# dsPIC33FJ64GS606 register map
Vendor: Microchip; Series: dsPIC33FJ64GS; File version: 1.4.228
Registers are 16-bit, read-write, no defined reset value unless marked. A register's access mark holds for its fields unless they carry their own. Offsets are from the block's base; [hi:lo] are bit positions; {n}, {i} and the like mark numbered series.

## CAN1 — CAN1 peripheral registers
Base 0x00000600
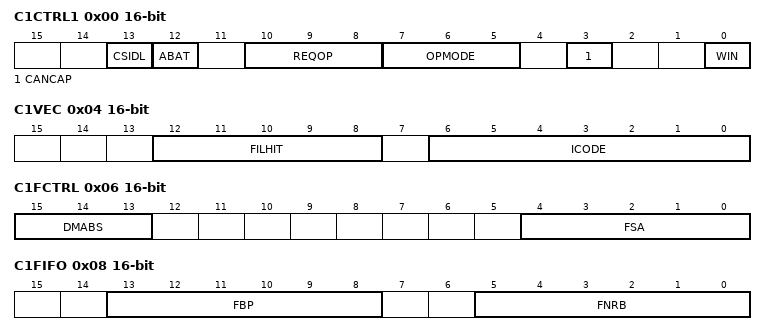
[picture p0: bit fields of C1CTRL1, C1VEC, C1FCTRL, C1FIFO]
0x00 C1CTRL1
  [13] CSIDL — C1CTRL1 field CSIDL
  [12] ABAT — C1CTRL1 field ABAT
  [10:8] REQOP — C1CTRL1 field REQOP
  [7:5] OPMODE — C1CTRL1 field OPMODE
  [3] CANCAP — C1CTRL1 field CANCAP
  [0] WIN — C1CTRL1 field WIN
0x02 C1CTRL2
  [4:0] DNCNT — C1CTRL2 field DNCNT
0x04 C1VEC
  [12:8] FILHIT — C1VEC field FILHIT
  [6:0] ICODE — C1VEC field ICODE
0x06 C1FCTRL
  [15:13] DMABS — C1FCTRL field DMABS
  [4:0] FSA — C1FCTRL field FSA
0x08 C1FIFO
  [13:8] FBP — C1FIFO field FBP
  [5:0] FNRB — C1FIFO field FNRB
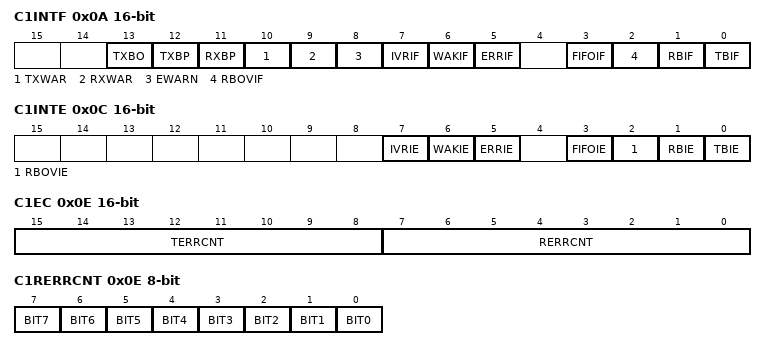
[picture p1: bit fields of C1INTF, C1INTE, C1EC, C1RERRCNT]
0x0A C1INTF
  [13] TXBO — C1INTF field TXBO
  [12] TXBP — C1INTF field TXBP
  [11] RXBP — C1INTF field RXBP
  [10] TXWAR — C1INTF field TXWAR
  [9] RXWAR — C1INTF field RXWAR
  [8] EWARN — C1INTF field EWARN
  [7] IVRIF — C1INTF field IVRIF
  [6] WAKIF — C1INTF field WAKIF
  [5] ERRIF — C1INTF field ERRIF
  [3] FIFOIF — C1INTF field FIFOIF
  [2] RBOVIF — C1INTF field RBOVIF
  [1] RBIF — C1INTF field RBIF
  [0] TBIF — C1INTF field TBIF
0x0C C1INTE
  [7] IVRIE — C1INTE field IVRIE
  [6] WAKIE — C1INTE field WAKIE
  [5] ERRIE — C1INTE field ERRIE
  [3] FIFOIE — C1INTE field FIFOIE
  [2] RBOVIE — C1INTE field RBOVIE
  [1] RBIE — C1INTE field RBIE
  [0] TBIE — C1INTE field TBIE
0x0E C1EC
  [15:8] TERRCNT — C1EC field TERRCNT
  [7:0] RERRCNT — C1EC field RERRCNT
0x0E C1RERRCNT 8-bit
  [n] BIT{n} (n=0..7) — C1RERRCNT bit {n}
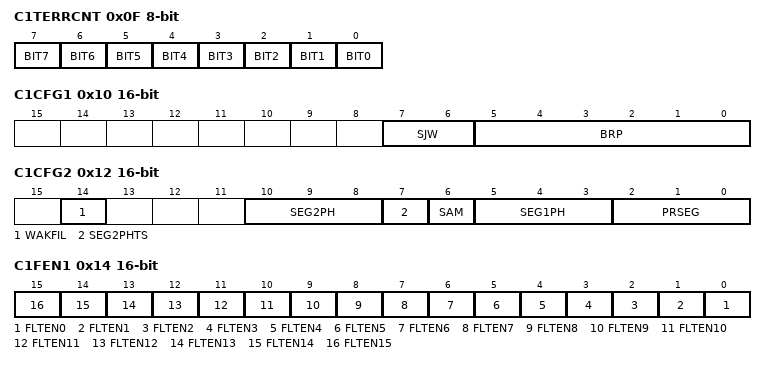
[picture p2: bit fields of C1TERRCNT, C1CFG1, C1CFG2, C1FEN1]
0x0F C1TERRCNT 8-bit
  [n] BIT{n} (n=0..7) — C1TERRCNT bit {n}
0x10 C1CFG1
  [7:6] SJW — C1CFG1 field SJW
  [5:0] BRP — C1CFG1 field BRP
0x12 C1CFG2
  [14] WAKFIL — C1CFG2 field WAKFIL
  [10:8] SEG2PH — C1CFG2 field SEG2PH
  [7] SEG2PHTS — C1CFG2 field SEG2PHTS
  [6] SAM — C1CFG2 field SAM
  [5:3] SEG1PH — C1CFG2 field SEG1PH
  [2:0] PRSEG — C1CFG2 field PRSEG
0x14 C1FEN1
  [n] FLTEN{n} (n=0..15) — C1FEN1 field FLTEN{n}
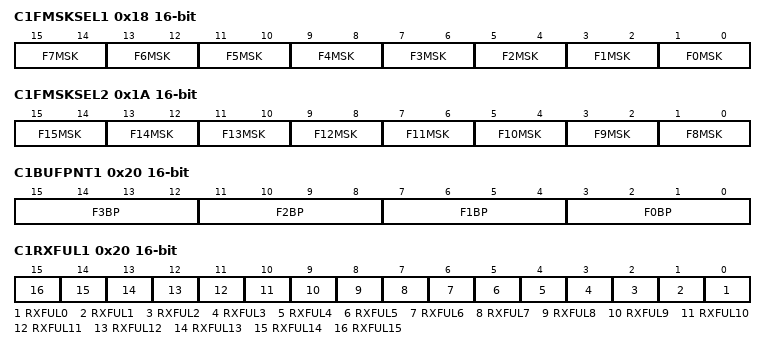
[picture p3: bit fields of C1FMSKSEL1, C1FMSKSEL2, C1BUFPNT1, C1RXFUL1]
0x18 C1FMSKSEL1
  [2n+1:2n] F{n}MSK (n=0..7) — C1FMSKSEL1 field F{n}MSK
0x1A C1FMSKSEL2
  [2n-15:2n-16] F{n}MSK (n=8..15) — C1FMSKSEL2 field F{n}MSK
0x20 C1BUFPNT1
  [4n+3:4n] F{n}BP (n=0..3) — C1BUFPNT1 field F{n}BP
0x20 C1RXFUL1
  [n] RXFUL{n} (n=0..15) — C1RXFUL1 field RXFUL{n}
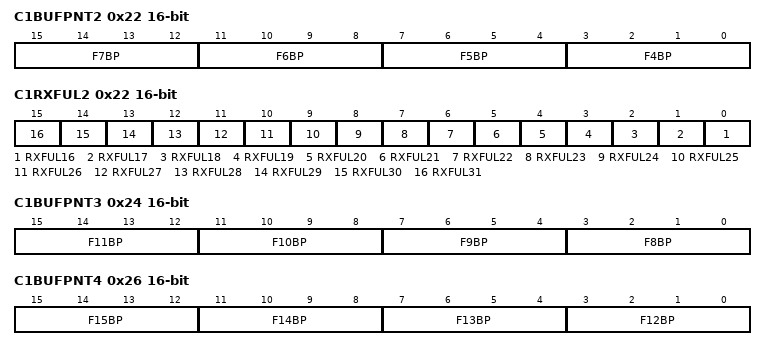
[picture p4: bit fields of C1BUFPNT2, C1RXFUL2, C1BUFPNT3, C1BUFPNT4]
0x22 C1BUFPNT2
  [4n-13:4n-16] F{n}BP (n=4..7) — C1BUFPNT2 field F{n}BP
0x22 C1RXFUL2
  [n-16] RXFUL{n} (n=16..31) — C1RXFUL2 field RXFUL{n}
0x24 C1BUFPNT3
  [4n-29:4n-32] F{n}BP (n=8..11) — C1BUFPNT3 field F{n}BP
0x26 C1BUFPNT4
  [4n-45:4n-48] F{n}BP (n=12..15) — C1BUFPNT4 field F{n}BP
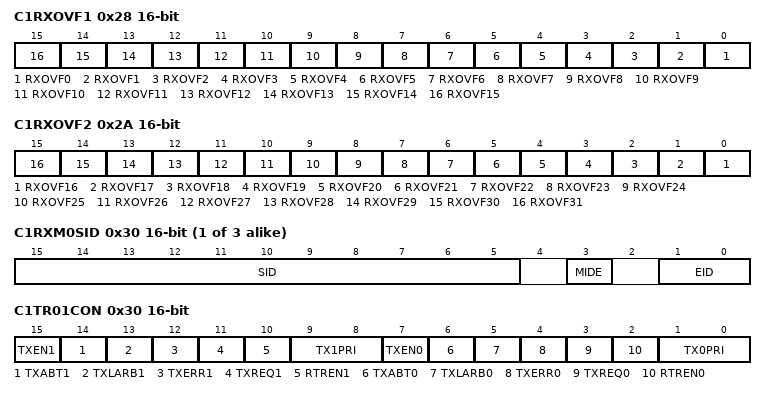
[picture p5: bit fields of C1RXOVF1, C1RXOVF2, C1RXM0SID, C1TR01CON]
0x28 C1RXOVF1
  [n] RXOVF{n} (n=0..15) — C1RXOVF1 field RXOVF{n}
0x2A C1RXOVF2
  [n-16] RXOVF{n} (n=16..31) — C1RXOVF2 field RXOVF{n}
{0x30+4i} C1RXM{i}SID (i=0..2)
  [15:5] SID — C1RXM{i}SID field SID
  [3] MIDE — C1RXM{i}SID field MIDE
  [1:0] EID — C1RXM{i}SID field EID
0x30 C1TR01CON
  [15] TXEN1 — C1TR01CON field TXEN1
  [14] TXABT1 — C1TR01CON field TXABT1
  [13] TXLARB1 — C1TR01CON field TXLARB1
  [12] TXERR1 — C1TR01CON field TXERR1
  [11] TXREQ1 — C1TR01CON field TXREQ1
  [10] RTREN1 — C1TR01CON field RTREN1
  [9:8] TX1PRI — C1TR01CON field TX1PRI
  [7] TXEN0 — C1TR01CON field TXEN0
  [6] TXABT0 — C1TR01CON field TXABT0
  [5] TXLARB0 — C1TR01CON field TXLARB0
  [4] TXERR0 — C1TR01CON field TXERR0
  [3] TXREQ0 — C1TR01CON field TXREQ0
  [2] RTREN0 — C1TR01CON field RTREN0
  [1:0] TX0PRI — C1TR01CON field TX0PRI
{0x32+4i} C1RXM{i}EID (i=0..2)
  [15:0] EID — C1RXM{i}EID field EID
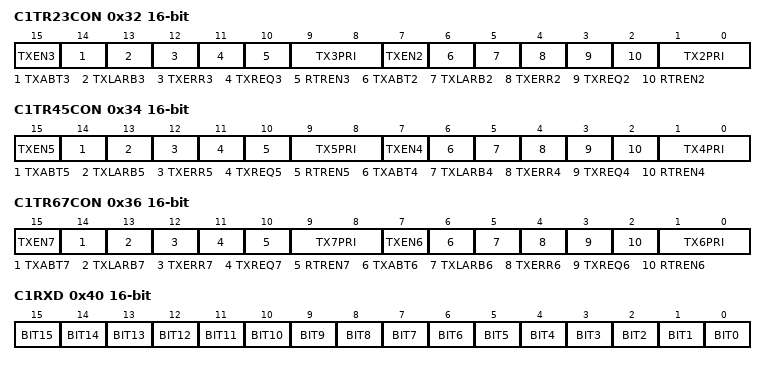
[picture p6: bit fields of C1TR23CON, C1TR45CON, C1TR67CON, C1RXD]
0x32 C1TR23CON
  [15] TXEN3 — C1TR23CON field TXEN3
  [14] TXABT3 — C1TR23CON field TXABT3
  [13] TXLARB3 — C1TR23CON field TXLARB3
  [12] TXERR3 — C1TR23CON field TXERR3
  [11] TXREQ3 — C1TR23CON field TXREQ3
  [10] RTREN3 — C1TR23CON field RTREN3
  [9:8] TX3PRI — C1TR23CON field TX3PRI
  [7] TXEN2 — C1TR23CON field TXEN2
  [6] TXABT2 — C1TR23CON field TXABT2
  [5] TXLARB2 — C1TR23CON field TXLARB2
  [4] TXERR2 — C1TR23CON field TXERR2
  [3] TXREQ2 — C1TR23CON field TXREQ2
  [2] RTREN2 — C1TR23CON field RTREN2
  [1:0] TX2PRI — C1TR23CON field TX2PRI
0x34 C1TR45CON
  [15] TXEN5 — C1TR45CON field TXEN5
  [14] TXABT5 — C1TR45CON field TXABT5
  [13] TXLARB5 — C1TR45CON field TXLARB5
  [12] TXERR5 — C1TR45CON field TXERR5
  [11] TXREQ5 — C1TR45CON field TXREQ5
  [10] RTREN5 — C1TR45CON field RTREN5
  [9:8] TX5PRI — C1TR45CON field TX5PRI
  [7] TXEN4 — C1TR45CON field TXEN4
  [6] TXABT4 — C1TR45CON field TXABT4
  [5] TXLARB4 — C1TR45CON field TXLARB4
  [4] TXERR4 — C1TR45CON field TXERR4
  [3] TXREQ4 — C1TR45CON field TXREQ4
  [2] RTREN4 — C1TR45CON field RTREN4
  [1:0] TX4PRI — C1TR45CON field TX4PRI
0x36 C1TR67CON
  [15] TXEN7 — C1TR67CON field TXEN7
  [14] TXABT7 — C1TR67CON field TXABT7
  [13] TXLARB7 — C1TR67CON field TXLARB7
  [12] TXERR7 — C1TR67CON field TXERR7
  [11] TXREQ7 — C1TR67CON field TXREQ7
  [10] RTREN7 — C1TR67CON field RTREN7
  [9:8] TX7PRI — C1TR67CON field TX7PRI
  [7] TXEN6 — C1TR67CON field TXEN6
  [6] TXABT6 — C1TR67CON field TXABT6
  [5] TXLARB6 — C1TR67CON field TXLARB6
  [4] TXERR6 — C1TR67CON field TXERR6
  [3] TXREQ6 — C1TR67CON field TXREQ6
  [2] RTREN6 — C1TR67CON field RTREN6
  [1:0] TX6PRI — C1TR67CON field TX6PRI
0x40 C1RXD
  [n] BIT{n} (n=0..15) — C1RXD bit {n}
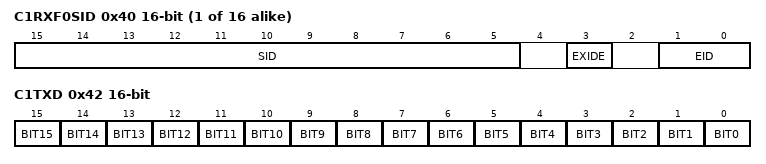
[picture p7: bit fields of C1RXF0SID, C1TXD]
{0x40+4i} C1RXF{i}SID (i=0..15)
  [15:5] SID — C1RXF{i}SID field SID
  [3] EXIDE — C1RXF{i}SID field EXIDE
  [1:0] EID — C1RXF{i}SID field EID
{0x42+4i} C1RXF{i}EID (i=0..15)
  [15:0] EID — C1RXF{i}EID field EID
0x42 C1TXD
  [n] BIT{n} (n=0..15) — C1TXD bit {n}
